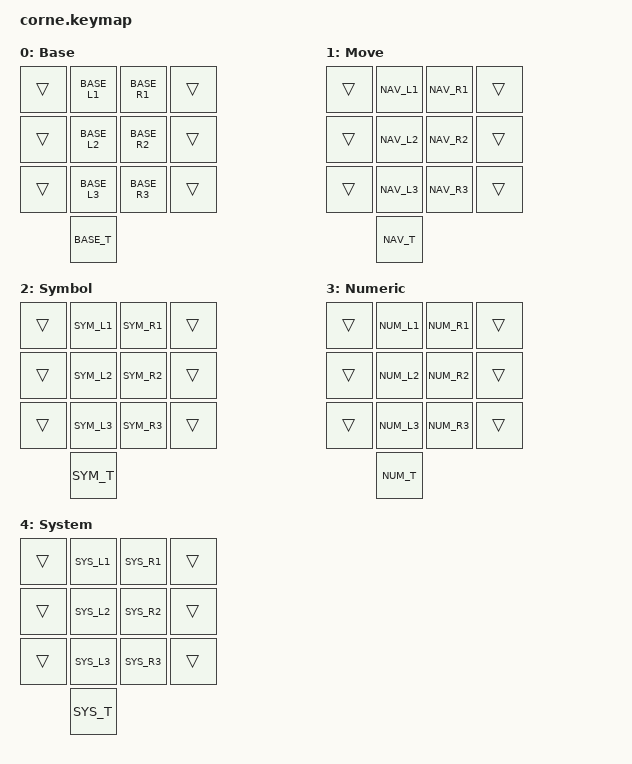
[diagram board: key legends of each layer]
#include <behaviors.dtsi>
#include <dt-bindings/zmk/bt.h>         // Bluetooth Command Defines
#include <dt-bindings/zmk/keys.h>       // Keycode Defines
#include <dt-bindings/zmk/ext_power.h>  // Power Management Behaviors
#include "mouse.dtsi"                   // Mouse emulation tuning and movement/scroll defines
#include "corne_positions.dtsi"         // Named key positions used by combos
#include "unicode.dtsi"                 // UNICODE_MACRO() helper for Ctrl+Shift+U input
#include "layers.dtsi"                  // Layer indices and the shared row macros (the layout)

#include "behaviors.dtsi"               // Shared hold-taps and mod-morphs
#include "macros.dtsi"                  // Shared macros
#include "combos.dtsi"                  // Shared combos

// The layout itself, with a diagram per layer, is in layers.dtsi. Each layer here adds only the
// corne's outer columns, which are unused (&trans) on every layer.
/ {
    keymap {
        compatible = "zmk,keymap";

        default_layer {
            display-name = "Base";
            bindings = <
&trans   BASE_L1   BASE_R1   &trans
&trans   BASE_L2   BASE_R2   &trans
&trans   BASE_L3   BASE_R3   &trans
         BASE_T
            >;
        };

        nav_layer {
            display-name = "Move";
            bindings = <
&trans   NAV_L1   NAV_R1   &trans
&trans   NAV_L2   NAV_R2   &trans
&trans   NAV_L3   NAV_R3   &trans
         NAV_T
            >;
        };

        symbol_layer {
            display-name = "Symbol";
            bindings = <
&trans   SYM_L1   SYM_R1   &trans
&trans   SYM_L2   SYM_R2   &trans
&trans   SYM_L3   SYM_R3   &trans
         SYM_T
            >;
        };

        numerical_layer {
            display-name = "Numeric";
            bindings = <
&trans   NUM_L1   NUM_R1   &trans
&trans   NUM_L2   NUM_R2   &trans
&trans   NUM_L3   NUM_R3   &trans
         NUM_T
            >;
        };

        system_layer {
            display-name = "System";
            bindings = <
&trans   SYS_L1   SYS_R1   &trans
&trans   SYS_L2   SYS_R2   &trans
&trans   SYS_L3   SYS_R3   &trans
         SYS_T
            >;
        };
    };
};
